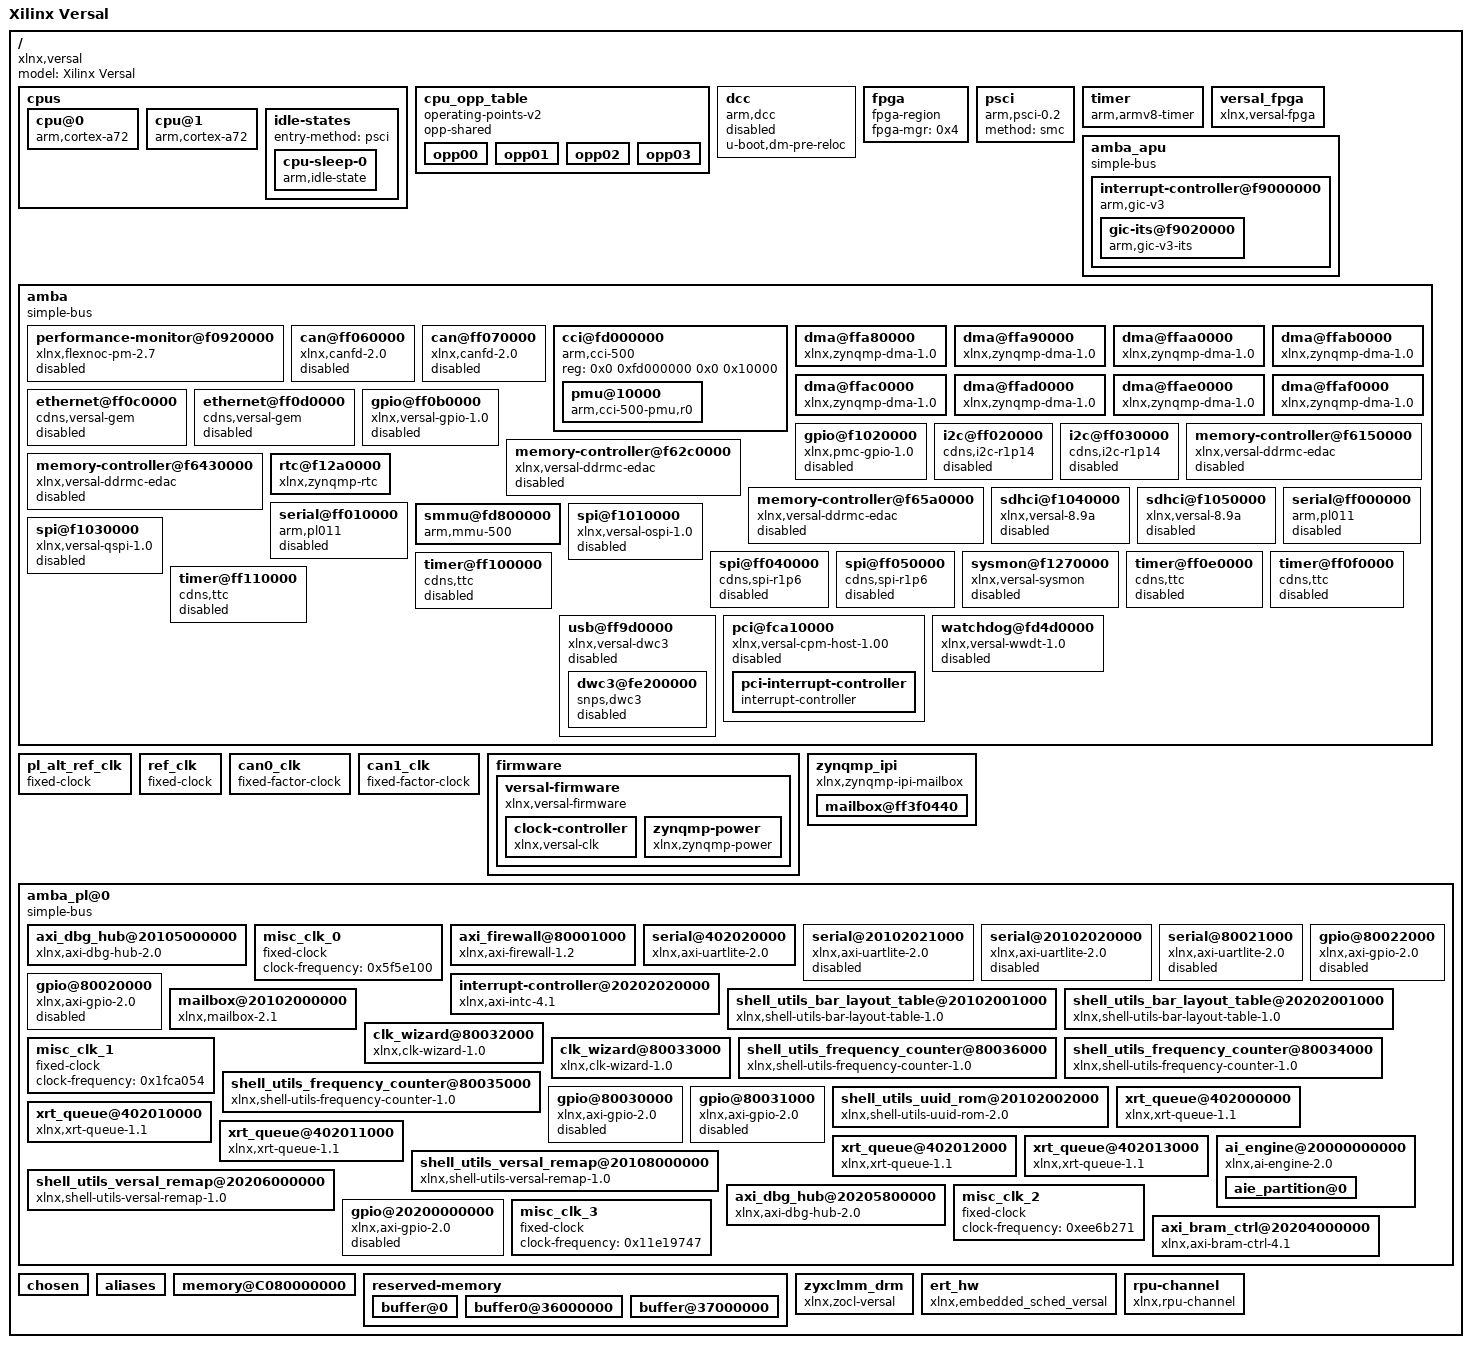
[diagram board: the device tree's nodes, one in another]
/dts-v1/;

/ {
	compatible = "xlnx,versal";
	#address-cells = <0x2>;
	#size-cells = <0x2>;
	model = "Xilinx Versal";

	cpus {
		#address-cells = <0x1>;
		#size-cells = <0x0>;

		cpu@0 {
			compatible = "arm,cortex-a72", "arm,armv8";
			device_type = "cpu";
			enable-method = "psci";
			operating-points-v2 = <0x1>;
			reg = <0x0>;
			cpu-idle-states = <0x2>;
			clocks = <0x3 0x4d>;
		};

		cpu@1 {
			compatible = "arm,cortex-a72", "arm,armv8";
			device_type = "cpu";
			enable-method = "psci";
			operating-points-v2 = <0x1>;
			reg = <0x1>;
			cpu-idle-states = <0x2>;
		};

		idle-states {
			entry-method = "psci";

			cpu-sleep-0 {
				compatible = "arm,idle-state";
				arm,psci-suspend-param = <0x40000000>;
				local-timer-stop;
				entry-latency-us = <0x12c>;
				exit-latency-us = <0x258>;
				min-residency-us = <0x2710>;
				phandle = <0x2>;
			};
		};
	};

	cpu_opp_table {
		compatible = "operating-points-v2";
		opp-shared;
		phandle = <0x1>;

		opp00 {
			opp-hz = <0x0 0x47868bf4>;
			opp-microvolt = <0xf4240>;
			clock-latency-ns = <0x7a120>;
		};

		opp01 {
			opp-hz = <0x0 0x23c345fa>;
			opp-microvolt = <0xf4240>;
			clock-latency-ns = <0x7a120>;
		};

		opp02 {
			opp-hz = <0x0 0x17d783fc>;
			opp-microvolt = <0xf4240>;
			clock-latency-ns = <0x7a120>;
		};

		opp03 {
			opp-hz = <0x0 0x11e1a2fd>;
			opp-microvolt = <0xf4240>;
			clock-latency-ns = <0x7a120>;
		};
	};

	dcc {
		compatible = "arm,dcc";
		status = "disabled";
		u-boot,dm-pre-reloc;
	};

	fpga {
		compatible = "fpga-region";
		fpga-mgr = <0x4>;
		#address-cells = <0x2>;
		#size-cells = <0x2>;
	};

	psci {
		compatible = "arm,psci-0.2";
		method = "smc";
	};

	timer {
		compatible = "arm,armv8-timer";
		interrupt-parent = <0x5>;
		interrupts = <0x1 0xd 0x4 0x1 0xe 0x4 0x1 0xb 0x4 0x1 0xa 0x4>;
	};

	versal_fpga {
		compatible = "xlnx,versal-fpga";
		phandle = <0x4>;
	};

	amba_apu {
		compatible = "simple-bus";
		#address-cells = <0x2>;
		#size-cells = <0x2>;
		ranges;

		interrupt-controller@f9000000 {
			compatible = "arm,gic-v3";
			#interrupt-cells = <0x3>;
			#address-cells = <0x2>;
			#size-cells = <0x2>;
			ranges;
			reg = <0x0 0xf9000000 0x0 0x80000 0x0 0xf9080000 0x0 0x80000>;
			interrupt-controller;
			interrupt-parent = <0x5>;
			interrupts = <0x1 0x9 0x4>;
			num_cpus = <0x2>;
			num_interrupts = <0x60>;
			phandle = <0x5>;

			gic-its@f9020000 {
				compatible = "arm,gic-v3-its";
				msi-controller;
				msi-cells = <0x1>;
				reg = <0x0 0xf9020000 0x0 0x20000>;
				phandle = <0xa>;
			};
		};
	};

	amba {
		compatible = "simple-bus";
		#address-cells = <0x2>;
		#size-cells = <0x2>;
		ranges;
		interrupt-parent = <0x5>;
		u-boot,dm-pre-reloc;

		performance-monitor@f0920000 {
			compatible = "xlnx,flexnoc-pm-2.7";
			status = "disabled";
			reg-names = "funnel", "baselpd", "basefpd";
			reg = <0x0 0xf0920000 0x0 0x1000 0x0 0xf0980000 0x0 0x9000 0x0 0xf0b80000 0x0 0x9000>;
		};

		can@ff060000 {
			compatible = "xlnx,canfd-2.0";
			status = "disabled";
			reg = <0x0 0xff060000 0x0 0x6000>;
			interrupts = <0x0 0x14 0x1>;
			clock-names = "can_clk", "s_axi_aclk";
			rx-fifo-depth = <0x40>;
			tx-mailbox-count = <0x20>;
			clocks = <0x6 0x3 0x52>;
			power-domains = <0x7 0x1822401f>;
		};

		can@ff070000 {
			compatible = "xlnx,canfd-2.0";
			status = "disabled";
			reg = <0x0 0xff070000 0x0 0x6000>;
			interrupts = <0x0 0x15 0x1>;
			clock-names = "can_clk", "s_axi_aclk";
			rx-fifo-depth = <0x40>;
			tx-mailbox-count = <0x20>;
			clocks = <0x8 0x3 0x52>;
			power-domains = <0x7 0x18224020>;
		};

		cci@fd000000 {
			compatible = "arm,cci-500";
			status = "okay";
			reg = <0x0 0xfd000000 0x0 0x10000>;
			ranges = <0x0 0x0 0xfd000000 0xa0000>;
			#address-cells = <0x1>;
			#size-cells = <0x1>;

			pmu@10000 {
				compatible = "arm,cci-500-pmu,r0";
				reg = <0x10000 0x90000>;
				interrupts = <0x0 0x6a 0x4 0x0 0x6a 0x4 0x0 0x6a 0x4 0x0 0x6a 0x4 0x0 0x6a 0x4 0x0 0x6a 0x4 0x0 0x6a 0x4 0x0 0x6a 0x4 0x0 0x6a 0x4>;
			};
		};

		dma@ffa80000 {
			compatible = "xlnx,zynqmp-dma-1.0";
			status = "okay";
			reg = <0x0 0xffa80000 0x0 0x1000>;
			interrupts = <0x0 0x3c 0x4>;
			clock-names = "clk_main", "clk_apb";
			#stream-id-cells = <0x1>;
			xlnx,bus-width = <0x40>;
			clocks = <0x3 0x51 0x3 0x52>;
			power-domains = <0x7 0x18224035>;
		};

		dma@ffa90000 {
			compatible = "xlnx,zynqmp-dma-1.0";
			status = "okay";
			reg = <0x0 0xffa90000 0x0 0x1000>;
			interrupts = <0x0 0x3d 0x4>;
			clock-names = "clk_main", "clk_apb";
			#stream-id-cells = <0x1>;
			xlnx,bus-width = <0x40>;
			clocks = <0x3 0x51 0x3 0x52>;
			power-domains = <0x7 0x18224036>;
		};

		dma@ffaa0000 {
			compatible = "xlnx,zynqmp-dma-1.0";
			status = "okay";
			reg = <0x0 0xffaa0000 0x0 0x1000>;
			interrupts = <0x0 0x3e 0x4>;
			clock-names = "clk_main", "clk_apb";
			#stream-id-cells = <0x1>;
			xlnx,bus-width = <0x40>;
			clocks = <0x3 0x51 0x3 0x52>;
			power-domains = <0x7 0x18224037>;
		};

		dma@ffab0000 {
			compatible = "xlnx,zynqmp-dma-1.0";
			status = "okay";
			reg = <0x0 0xffab0000 0x0 0x1000>;
			interrupts = <0x0 0x3f 0x4>;
			clock-names = "clk_main", "clk_apb";
			#stream-id-cells = <0x1>;
			xlnx,bus-width = <0x40>;
			clocks = <0x3 0x51 0x3 0x52>;
			power-domains = <0x7 0x18224038>;
		};

		dma@ffac0000 {
			compatible = "xlnx,zynqmp-dma-1.0";
			status = "okay";
			reg = <0x0 0xffac0000 0x0 0x1000>;
			interrupts = <0x0 0x40 0x4>;
			clock-names = "clk_main", "clk_apb";
			#stream-id-cells = <0x1>;
			xlnx,bus-width = <0x40>;
			clocks = <0x3 0x51 0x3 0x52>;
			power-domains = <0x7 0x18224039>;
		};

		dma@ffad0000 {
			compatible = "xlnx,zynqmp-dma-1.0";
			status = "okay";
			reg = <0x0 0xffad0000 0x0 0x1000>;
			interrupts = <0x0 0x41 0x4>;
			clock-names = "clk_main", "clk_apb";
			#stream-id-cells = <0x1>;
			xlnx,bus-width = <0x40>;
			clocks = <0x3 0x51 0x3 0x52>;
			power-domains = <0x7 0x1822403a>;
		};

		dma@ffae0000 {
			compatible = "xlnx,zynqmp-dma-1.0";
			status = "okay";
			reg = <0x0 0xffae0000 0x0 0x1000>;
			interrupts = <0x0 0x42 0x4>;
			clock-names = "clk_main", "clk_apb";
			#stream-id-cells = <0x1>;
			xlnx,bus-width = <0x40>;
			clocks = <0x3 0x51 0x3 0x52>;
			power-domains = <0x7 0x1822403b>;
		};

		dma@ffaf0000 {
			compatible = "xlnx,zynqmp-dma-1.0";
			status = "okay";
			reg = <0x0 0xffaf0000 0x0 0x1000>;
			interrupts = <0x0 0x43 0x4>;
			clock-names = "clk_main", "clk_apb";
			#stream-id-cells = <0x1>;
			xlnx,bus-width = <0x40>;
			clocks = <0x3 0x51 0x3 0x52>;
			power-domains = <0x7 0x1822403c>;
		};

		ethernet@ff0c0000 {
			compatible = "cdns,versal-gem";
			status = "disabled";
			reg = <0x0 0xff0c0000 0x0 0x1000>;
			interrupts = <0x0 0x38 0x4 0x0 0x38 0x4>;
			clock-names = "pclk", "hclk", "tx_clk", "rx_clk", "tsu_clk";
			#stream-id-cells = <0x1>;
			#address-cells = <0x1>;
			#size-cells = <0x0>;
			clocks = <0x3 0x52 0x3 0x58 0x3 0x31 0x3 0x30 0x3 0x2b>;
			power-domains = <0x7 0x18224019>;
		};

		ethernet@ff0d0000 {
			compatible = "cdns,versal-gem";
			status = "disabled";
			reg = <0x0 0xff0d0000 0x0 0x1000>;
			interrupts = <0x0 0x3a 0x4 0x0 0x3a 0x4>;
			clock-names = "pclk", "hclk", "tx_clk", "rx_clk", "tsu_clk";
			#stream-id-cells = <0x1>;
			#address-cells = <0x1>;
			#size-cells = <0x0>;
			clocks = <0x3 0x52 0x3 0x59 0x3 0x33 0x3 0x32 0x3 0x2b>;
			power-domains = <0x7 0x1822401a>;
		};

		gpio@ff0b0000 {
			compatible = "xlnx,versal-gpio-1.0";
			status = "disabled";
			reg = <0x0 0xff0b0000 0x0 0x1000>;
			interrupts = <0x0 0xd 0x4>;
			#gpio-cells = <0x2>;
			gpio-controller;
			#interrupt-cells = <0x2>;
			interrupt-controller;
			clocks = <0x3 0x52>;
			power-domains = <0x7 0x18224023>;
		};

		gpio@f1020000 {
			compatible = "xlnx,pmc-gpio-1.0";
			status = "disabled";
			reg = <0x0 0xf1020000 0x0 0x1000>;
			interrupts = <0x0 0x7a 0x4>;
			#gpio-cells = <0x2>;
			gpio-controller;
			#interrupt-cells = <0x2>;
			interrupt-controller;
			clocks = <0x3 0x3d>;
			power-domains = <0x7 0x1822402c>;
		};

		i2c@ff020000 {
			compatible = "cdns,i2c-r1p14", "cdns,i2c-r1p10";
			status = "disabled";
			reg = <0x0 0xff020000 0x0 0x1000>;
			interrupts = <0x0 0xe 0x4>;
			clock-frequency = <0x61a80>;
			#address-cells = <0x1>;
			#size-cells = <0x0>;
			clocks = <0x3 0x62>;
			power-domains = <0x7 0x1822401d>;
		};

		i2c@ff030000 {
			compatible = "cdns,i2c-r1p14", "cdns,i2c-r1p10";
			status = "disabled";
			reg = <0x0 0xff030000 0x0 0x1000>;
			interrupts = <0x0 0xf 0x4>;
			clock-frequency = <0x61a80>;
			#address-cells = <0x1>;
			#size-cells = <0x0>;
			clocks = <0x3 0x63>;
			power-domains = <0x7 0x1822401e>;
		};

		memory-controller@f6150000 {
			compatible = "xlnx,versal-ddrmc-edac";
			status = "disabled";
			reg = <0x0 0xf6150000 0x0 0x2000 0x0 0xf6070000 0x0 0x20000>;
			reg-names = "ddrmc_base", "ddrmc_noc_base";
			interrupt-parent = <0x5>;
			interrupts = <0x0 0x93 0x4>;
			xlnx,mc-id = <0x0>;
		};

		memory-controller@f62c0000 {
			compatible = "xlnx,versal-ddrmc-edac";
			status = "disabled";
			reg = <0x0 0xf62c0000 0x0 0x2000 0x0 0xf6210000 0x0 0x20000>;
			reg-names = "ddrmc_base", "ddrmc_noc_base";
			interrupt-parent = <0x5>;
			interrupts = <0x0 0x93 0x4>;
			xlnx,mc-id = <0x1>;
		};

		memory-controller@f6430000 {
			compatible = "xlnx,versal-ddrmc-edac";
			status = "disabled";
			reg = <0x0 0xf6430000 0x0 0x2000 0x0 0xf6380000 0x0 0x20000>;
			reg-names = "ddrmc_base", "ddrmc_noc_base";
			interrupt-parent = <0x5>;
			interrupts = <0x0 0x93 0x4>;
			xlnx,mc-id = <0x2>;
		};

		memory-controller@f65a0000 {
			compatible = "xlnx,versal-ddrmc-edac";
			status = "disabled";
			reg = <0x0 0xf65a0000 0x0 0x2000 0x0 0xf64f0000 0x0 0x20000>;
			reg-names = "ddrmc_base", "ddrmc_noc_base";
			interrupt-parent = <0x5>;
			interrupts = <0x0 0x93 0x4>;
			xlnx,mc-id = <0x3>;
		};

		rtc@f12a0000 {
			compatible = "xlnx,zynqmp-rtc";
			status = "okay";
			reg = <0x0 0xf12a0000 0x0 0x100>;
			interrupt-names = "alarm", "sec";
			interrupts = <0x0 0x8e 0x4 0x0 0x8f 0x4>;
			calibration = <0x8000>;
			power-domains = <0x7 0x18224034>;
		};

		sdhci@f1040000 {
			compatible = "xlnx,versal-8.9a", "arasan,sdhci-8.9a";
			status = "disabled";
			reg = <0x0 0xf1040000 0x0 0x10000>;
			interrupts = <0x0 0x7e 0x4 0x0 0x7e 0x4>;
			clock-names = "clk_xin", "clk_ahb";
			xlnx,device_id = <0x0>;
			#stream-id-cells = <0x1>;
			#clock-cells = <0x1>;
			clock-output-names = "clk_out_sd0", "clk_in_sd0";
			clocks = <0x3 0x3b 0x3 0x52>;
			power-domains = <0x7 0x1822402e>;
		};

		sdhci@f1050000 {
			compatible = "xlnx,versal-8.9a", "arasan,sdhci-8.9a";
			status = "disabled";
			reg = <0x0 0xf1050000 0x0 0x10000>;
			interrupts = <0x0 0x80 0x4 0x0 0x80 0x4>;
			clock-names = "clk_xin", "clk_ahb";
			xlnx,device_id = <0x1>;
			#stream-id-cells = <0x1>;
			#clock-cells = <0x1>;
			clock-output-names = "clk_out_sd1", "clk_in_sd1";
			clocks = <0x3 0x3c 0x3 0x52>;
			power-domains = <0x7 0x1822402f>;
		};

		serial@ff000000 {
			compatible = "arm,pl011", "arm,sbsa-uart";
			status = "disabled";
			reg = <0x0 0xff000000 0x0 0x1000>;
			interrupts = <0x0 0x12 0x4>;
			clock-names = "uart_clk", "apb_clk";
			current-speed = <0x1c200>;
			u-boot,dm-pre-reloc;
			clocks = <0x3 0x5c 0x3 0x52>;
			power-domains = <0x7 0x18224021>;
			cts-override;
			device_type = "serial";
			port-number = <0x1>;
		};

		serial@ff010000 {
			compatible = "arm,pl011", "arm,sbsa-uart";
			status = "disabled";
			reg = <0x0 0xff010000 0x0 0x1000>;
			interrupts = <0x0 0x13 0x4>;
			clock-names = "uart_clk", "apb_clk";
			current-speed = <0x1c200>;
			u-boot,dm-pre-reloc;
			clocks = <0x3 0x5d 0x3 0x52>;
			power-domains = <0x7 0x18224022>;
			cts-override;
			device_type = "serial";
			port-number = <0x0>;
		};

		smmu@fd800000 {
			compatible = "arm,mmu-500";
			status = "okay";
			reg = <0x0 0xfd800000 0x0 0x40000>;
			stream-match-mask = <0x7c00>;
			#iommu-cells = <0x1>;
			#global-interrupts = <0x1>;
			interrupts = <0x0 0x6b 0x4 0x0 0x6b 0x4 0x0 0x6b 0x4 0x0 0x6b 0x4 0x0 0x6b 0x4 0x0 0x6b 0x4 0x0 0x6b 0x4 0x0 0x6b 0x4 0x0 0x6b 0x4 0x0 0x6b 0x4 0x0 0x6b 0x4 0x0 0x6b 0x4 0x0 0x6b 0x4 0x0 0x6b 0x4 0x0 0x6b 0x4 0x0 0x6b 0x4 0x0 0x6b 0x4 0x0 0x6b 0x4 0x0 0x6b 0x4 0x0 0x6b 0x4 0x0 0x6b 0x4 0x0 0x6b 0x4 0x0 0x6b 0x4 0x0 0x6b 0x4 0x0 0x6b 0x4 0x0 0x6b 0x4 0x0 0x6b 0x4 0x0 0x6b 0x4 0x0 0x6b 0x4 0x0 0x6b 0x4 0x0 0x6b 0x4 0x0 0x6b 0x4 0x0 0x6b 0x4>;
		};

		spi@f1010000 {
			compatible = "xlnx,versal-ospi-1.0", "cadence,qspi", "cdns,qspi-nor";
			status = "disabled";
			reg = <0x0 0xf1010000 0x0 0x10000 0x0 0xc0000000 0x0 0x20000000>;
			interrupts = <0x0 0x7c 0x4 0x0 0x7c 0x4>;
			clock-names = "ref_clk", "pclk";
			cdns,fifo-depth = <0x100>;
			cdns,fifo-width = <0x4>;
			cdns,is-dma = <0x1>;
			cdns,is-stig-pgm = <0x1>;
			cdns,trigger-address = <0xc0000000>;
			#stream-id-cells = <0x1>;
			#address-cells = <0x1>;
			#size-cells = <0x0>;
			clocks = <0x3 0x3a 0x3 0x52>;
			power-domains = <0x7 0x1822402a>;
			is-dual = <0x0>;
			is-stacked = <0x0>;
		};

		spi@f1030000 {
			compatible = "xlnx,versal-qspi-1.0";
			status = "disabled";
			reg = <0x0 0xf1030000 0x0 0x1000>;
			interrupts = <0x0 0x7d 0x4 0x0 0x7d 0x4>;
			clock-names = "ref_clk", "pclk";
			#stream-id-cells = <0x1>;
			#address-cells = <0x1>;
			#size-cells = <0x0>;
			clocks = <0x3 0x39 0x3 0x52>;
			power-domains = <0x7 0x1822402b>;
		};

		spi@ff040000 {
			compatible = "cdns,spi-r1p6";
			status = "disabled";
			reg = <0x0 0xff040000 0x0 0x1000>;
			interrupts = <0x0 0x10 0x4>;
			clock-names = "ref_clk", "pclk";
			#address-cells = <0x1>;
			#size-cells = <0x0>;
			clocks = <0x3 0x5e 0x3 0x52>;
			power-domains = <0x7 0x1822401b>;
		};

		spi@ff050000 {
			compatible = "cdns,spi-r1p6";
			status = "disabled";
			reg = <0x0 0xff050000 0x0 0x1000>;
			interrupts = <0x0 0x11 0x4>;
			clock-names = "ref_clk", "pclk";
			#address-cells = <0x1>;
			#size-cells = <0x0>;
			clocks = <0x3 0x5f 0x3 0x52>;
			power-domains = <0x7 0x1822401c>;
		};

		sysmon@f1270000 {
			compatible = "xlnx,versal-sysmon";
			status = "disabled";
			reg = <0x0 0xf1270000 0x0 0x4000>;
			interrupts = <0x0 0x90 0x4>;
			xlnx,numchannels = [00];
			#address-cells = <0x1>;
			#size-cells = <0x0>;
		};

		timer@ff0e0000 {
			compatible = "cdns,ttc";
			status = "disabled";
			interrupts = <0x0 0x25 0x4 0x0 0x26 0x4 0x0 0x27 0x4>;
			reg = <0x0 0xff0e0000 0x0 0x1000>;
			timer-width = <0x20>;
			clocks = <0x3 0x27 0x3 0x52>;
			power-domains = <0x7 0x18224024>;
		};

		timer@ff0f0000 {
			compatible = "cdns,ttc";
			status = "disabled";
			interrupts = <0x0 0x28 0x4 0x0 0x29 0x4 0x0 0x2a 0x4>;
			reg = <0x0 0xff0f0000 0x0 0x1000>;
			timer-width = <0x20>;
			clocks = <0x3 0x28 0x3 0x52>;
			power-domains = <0x7 0x18224025>;
		};

		timer@ff100000 {
			compatible = "cdns,ttc";
			status = "disabled";
			interrupts = <0x0 0x2b 0x4 0x0 0x2c 0x4 0x0 0x2d 0x4>;
			reg = <0x0 0xff100000 0x0 0x1000>;
			timer-width = <0x20>;
			clocks = <0x3 0x29 0x3 0x52>;
			power-domains = <0x7 0x18224026>;
		};

		timer@ff110000 {
			compatible = "cdns,ttc";
			status = "disabled";
			interrupts = <0x0 0x2e 0x4 0x0 0x2f 0x4 0x0 0x30 0x4>;
			reg = <0x0 0xff110000 0x0 0x1000>;
			timer-width = <0x20>;
			clocks = <0x3 0x2a 0x3 0x52>;
			power-domains = <0x7 0x18224027>;
		};

		usb@ff9d0000 {
			compatible = "xlnx,versal-dwc3";
			status = "disabled";
			reg = <0x0 0xff9d0000 0x0 0x100>;
			clock-names = "bus_clk", "ref_clk";
			ranges;
			#address-cells = <0x2>;
			#size-cells = <0x2>;
			clocks = <0x3 0x5b 0x3 0x68>;
			power-domains = <0x7 0x18224018>;

			dwc3@fe200000 {
				compatible = "snps,dwc3";
				status = "disabled";
				reg = <0x0 0xfe200000 0x0 0x10000>;
				interrupt-names = "dwc_usb3", "otg", "usb-wakeup";
				interrupts = <0x0 0x16 0x4 0x0 0x1a 0x4 0x0 0x4a 0x4>;
				#stream-id-cells = <0x1>;
				snps,dis_u2_susphy_quirk;
				snps,dis_u3_susphy_quirk;
				snps,quirk-frame-length-adjustment = <0x20>;
				snps,refclk_fladj;
				snps,mask_phy_reset;
			};
		};

		pci@fca10000 {
			#address-cells = <0x3>;
			#interrupt-cells = <0x1>;
			#size-cells = <0x2>;
			compatible = "xlnx,versal-cpm-host-1.00";
			status = "disabled";
			interrupt-map = <0x0 0x0 0x0 0x1 0x9 0x1 0x0 0x0 0x0 0x2 0x9 0x2 0x0 0x0 0x0 0x3 0x9 0x3 0x0 0x0 0x0 0x4 0x9 0x4>;
			interrupt-map-mask = <0x0 0x0 0x0 0x7>;
			interrupt-parent = <0x5>;
			interrupt-names = "misc";
			interrupts = <0x0 0x48 0x4>;
			ranges = <0x2000000 0x0 0xe0000000 0x0 0xe0000000 0x0 0x10000000 0x43000000 0x80 0x0 0x80 0x0 0x0 0x80000000>;
			msi-map = <0x0 0xa 0x0 0x10000>;
			reg = <0x0 0xfca10000 0x0 0x1000 0x6 0x0 0x0 0x1000000>;
			reg-names = "cpm_slcr", "cfg";

			pci-interrupt-controller {
				#address-cells = <0x0>;
				#interrupt-cells = <0x1>;
				interrupt-controller;
				phandle = <0x9>;
			};
		};

		watchdog@fd4d0000 {
			compatible = "xlnx,versal-wwdt-1.0";
			status = "disabled";
			reg = <0x0 0xfd4d0000 0x0 0x10000>;
			interrupt-names = "wdt", "wwdt_reset_pending";
			interrupts = <0x0 0x64 0x1 0x0 0x6d 0x1>;
			timeout-sec = <0x1e>;
			pretimeout-sec = <0x19>;
			clocks = <0x3 0x52>;
			power-domains = <0x7 0x18224029>;
		};
	};

	pl_alt_ref_clk {
		u-boot,dm-pre-reloc;
		compatible = "fixed-clock";
		#clock-cells = <0x0>;
		clock-frequency = <0x1fca055>;
		phandle = <0xc>;
	};

	ref_clk {
		u-boot,dm-pre-reloc;
		compatible = "fixed-clock";
		#clock-cells = <0x0>;
		clock-frequency = <0x1fca055>;
		phandle = <0xb>;
	};

	can0_clk {
		#clock-cells = <0x0>;
		compatible = "fixed-factor-clock";
		clocks = <0x3 0x60>;
		clock-div = <0x2>;
		clock-mult = <0x1>;
		phandle = <0x6>;
	};

	can1_clk {
		#clock-cells = <0x0>;
		compatible = "fixed-factor-clock";
		clocks = <0x3 0x61>;
		clock-div = <0x2>;
		clock-mult = <0x1>;
		phandle = <0x8>;
	};

	firmware {

		versal-firmware {
			compatible = "xlnx,versal-firmware";
			u-boot,dm-pre-reloc;
			method = "smc";
			#power-domain-cells = <0x1>;
			interrupt-parent = <0x5>;
			phandle = <0x7>;

			clock-controller {
				u-boot,dm-pre-reloc;
				#clock-cells = <0x1>;
				compatible = "xlnx,versal-clk";
				clocks = <0xb 0xc>;
				clock-names = "ref_clk", "pl_alt_ref_clk";
				phandle = <0x3>;
			};

			zynqmp-power {
				compatible = "xlnx,zynqmp-power";
				interrupt-parent = <0x5>;
				interrupts = <0x0 0x1e 0x4>;
				mboxes = <0xd 0x0 0xd 0x1>;
				mbox-names = "tx", "rx";
			};
		};
	};

	zynqmp_ipi {
		compatible = "xlnx,zynqmp-ipi-mailbox";
		interrupt-parent = <0x5>;
		interrupts = <0x0 0x1e 0x4>;
		xlnx,ipi-id = <0x2>;
		#address-cells = <0x2>;
		#size-cells = <0x2>;
		ranges;

		mailbox@ff3f0440 {
			reg = <0x0 0xff3f0440 0x0 0x20 0x0 0xff3f0460 0x0 0x20 0x0 0xff3f0280 0x0 0x20 0x0 0xff3f02a0 0x0 0x20>;
			reg-names = "local_request_region", "local_response_region", "remote_request_region", "remote_response_region";
			#mbox-cells = <0x1>;
			xlnx,ipi-id = <0x1>;
			phandle = <0xd>;
		};
	};

	amba_pl@0 {
		#address-cells = <0x2>;
		#size-cells = <0x2>;
		compatible = "simple-bus";
		ranges;

		axi_dbg_hub@20105000000 {
			clock-names = "aclk";
			clocks = <0xe>;
			compatible = "xlnx,axi-dbg-hub-2.0";
			reg = <0x201 0x5000000 0x0 0x200000>;
			xlnx,addr-offset = <0x201 0x5000000>;
			xlnx,addr-range = <0x200000>;
			xlnx,axi-addr-width = <0x40>;
			xlnx,axi-data-width = <0x80>;
			xlnx,axi-id-width = <0x2>;
			xlnx,axis-tdata-width = <0x20>;
			xlnx,num-debug-cores = <0x0>;
			xlnx,num-rd-outstanding-txn = <0x1>;
			xlnx,num-wr-outstanding-txn = <0x1>;
		};

		misc_clk_0 {
			#clock-cells = <0x0>;
			clock-frequency = <0x5f5e100>;
			compatible = "fixed-clock";
			phandle = <0xe>;
		};

		axi_firewall@80001000 {
			clock-names = "aclk";
			clocks = <0xe>;
			compatible = "xlnx,axi-firewall-1.2";
			reg = <0x0 0x80001000 0x0 0x1000>;
			xlnx,addr-width = <0x40>;
			xlnx,aruser-width = <0x0>;
			xlnx,awuser-width = <0x0>;
			xlnx,buser-width = <0x0>;
			xlnx,enable-ctl-clock = <0x0>;
			xlnx,enable-initial-delay = <0x1>;
			xlnx,enable-pipelining = <0x1>;
			xlnx,enable-prescaler = <0x1>;
			xlnx,enable-protocol-checks = <0x1>;
			xlnx,enable-timeout-checks = <0x1>;
			xlnx,firewall-mode = <0x0>;
			xlnx,id-width = <0x0>;
			xlnx,mask-err-resp = <0x1>;
			xlnx,num-read-outstanding = <0x20>;
			xlnx,num-read-threads = <0x1>;
			xlnx,num-write-outstanding = <0x20>;
			xlnx,num-write-threads = <0x1>;
			xlnx,protocol = <0x2>;
			xlnx,rdata-width = <0x20>;
			xlnx,ruser-width = <0x0>;
			xlnx,wdata-width = <0x20>;
			xlnx,wuser-width = <0x0>;
		};

		serial@402020000 {
			clock-names = "s_axi_aclk";
			clocks = <0xe>;
			compatible = "xlnx,axi-uartlite-2.0", "xlnx,xps-uartlite-1.00.a";
			current-speed = <0x38400>;
			device_type = "serial";
			interrupt-names = "interrupt";
			interrupt-parent = <0x5>;
			interrupts = <0x0 0x5e 0x1>;
			port-number = <0x0>;
			reg = <0x4 0x2020000 0x0 0x1000>;
			xlnx,baudrate = <0x38400>;
			xlnx,data-bits = <0x8>;
			xlnx,odd-parity = <0x0>;
			xlnx,s-axi-aclk-freq-hz-d = "100.0";
			xlnx,use-parity = <0x0>;
		};

		serial@20102021000 {
			status = "disabled";
			clock-names = "s_axi_aclk";
			clocks = <0xe>;
			compatible = "xlnx,axi-uartlite-2.0", "xlnx,xps-uartlite-1.00.a";
			current-speed = <0x38400>;
			device_type = "serial";
			port-number = <0x2>;
			reg = <0x201 0x2021000 0x0 0x1000>;
			xlnx,baudrate = <0x38400>;
			xlnx,data-bits = <0x8>;
			xlnx,odd-parity = <0x0>;
			xlnx,s-axi-aclk-freq-hz-d = "100.0";
			xlnx,use-parity = <0x0>;
		};

		serial@20102020000 {
			status = "disabled";
			clock-names = "s_axi_aclk";
			clocks = <0xe>;
			compatible = "xlnx,axi-uartlite-2.0", "xlnx,xps-uartlite-1.00.a";
			current-speed = <0x38400>;
			device_type = "serial";
			port-number = <0x3>;
			reg = <0x201 0x2020000 0x0 0x1000>;
			xlnx,baudrate = <0x38400>;
			xlnx,data-bits = <0x8>;
			xlnx,odd-parity = <0x0>;
			xlnx,s-axi-aclk-freq-hz-d = "100.0";
			xlnx,use-parity = <0x0>;
		};

		serial@80021000 {
			status = "disabled";
			clock-names = "s_axi_aclk";
			clocks = <0xe>;
			compatible = "xlnx,axi-uartlite-2.0", "xlnx,xps-uartlite-1.00.a";
			current-speed = <0x38400>;
			device_type = "serial";
			port-number = <0x4>;
			reg = <0x0 0x80021000 0x0 0x1000>;
			xlnx,baudrate = <0x38400>;
			xlnx,data-bits = <0x8>;
			xlnx,odd-parity = <0x0>;
			xlnx,s-axi-aclk-freq-hz-d = "100.0";
			xlnx,use-parity = <0x0>;
		};

		gpio@80022000 {
			status = "disabled";
			#gpio-cells = <0x3>;
			clock-names = "s_axi_aclk";
			clocks = <0xe>;
			compatible = "xlnx,axi-gpio-2.0", "xlnx,xps-gpio-1.00.a";
			gpio-controller;
			reg = <0x0 0x80022000 0x0 0x1000>;
			xlnx,all-inputs = <0x0>;
			xlnx,all-inputs-2 = <0x1>;
			xlnx,all-outputs = <0x1>;
			xlnx,all-outputs-2 = <0x0>;
			xlnx,dout-default = <0x0>;
			xlnx,dout-default-2 = <0x0>;
			xlnx,gpio-width = <0x1>;
			xlnx,gpio2-width = <0x1>;
			xlnx,interrupt-present = <0x0>;
			xlnx,is-dual = <0x1>;
			xlnx,tri-default = <0xffffffff>;
			xlnx,tri-default-2 = <0xffffffff>;
		};

		gpio@80020000 {
			status = "disabled";
			#gpio-cells = <0x3>;
			clock-names = "s_axi_aclk";
			clocks = <0xe>;
			compatible = "xlnx,axi-gpio-2.0", "xlnx,xps-gpio-1.00.a";
			gpio-controller;
			reg = <0x0 0x80020000 0x0 0x1000>;
			xlnx,all-inputs = <0x0>;
			xlnx,all-inputs-2 = <0x1>;
			xlnx,all-outputs = <0x1>;
			xlnx,all-outputs-2 = <0x0>;
			xlnx,dout-default = <0xffffffff>;
			xlnx,dout-default-2 = <0x0>;
			xlnx,gpio-width = <0x2>;
			xlnx,gpio2-width = <0x2>;
			xlnx,interrupt-present = <0x0>;
			xlnx,is-dual = <0x1>;
			xlnx,tri-default = <0xffffffff>;
			xlnx,tri-default-2 = <0xffffffff>;
		};

		interrupt-controller@20202020000 {
			#interrupt-cells = <0x2>;
			clock-names = "s_axi_aclk";
			clocks = <0xe>;
			compatible = "xlnx,axi-intc-4.1", "xlnx,xps-intc-1.00.a";
			interrupt-controller;
			interrupt-names = "irq";
			interrupt-parent = <0x5>;
			interrupts = <0x0 0x5d 0x4>;
			reg = <0x202 0x2020000 0x0 0x1000>;
			xlnx,kind-of-intr = <0xffffffff>;
			xlnx,num-intr-inputs = <0x20>;
		};

		shell_utils_bar_layout_table@20102001000 {
			clock-names = "S_AXI_ACLK";
			clocks = <0xe>;
			compatible = "xlnx,shell-utils-bar-layout-table-1.0";
			reg = <0x201 0x2001000 0x0 0x1000>;
			xlnx,entry-addr-0 = <0x0 0x2002000>;
			xlnx,entry-addr-1 = <0x0 0x2000000>;
			xlnx,entry-addr-2 = <0x0 0x2010000>;
			xlnx,entry-addr-3 = <0x0 0x8000000>;
			xlnx,entry-addr-4 = <0x0 0x0>;
			xlnx,entry-addr-5 = <0x0 0x0>;
			xlnx,entry-bar-0 = <0x0>;
			xlnx,entry-bar-1 = <0x0>;
			xlnx,entry-bar-2 = <0x0>;
			xlnx,entry-bar-3 = <0x0>;
			xlnx,entry-bar-4 = <0x0>;
			xlnx,entry-bar-5 = <0x0>;
			xlnx,entry-major-version-0 = <0x1>;
			xlnx,entry-major-version-1 = <0x1>;
			xlnx,entry-major-version-2 = <0x1>;
			xlnx,entry-major-version-3 = <0x1>;
			xlnx,entry-major-version-4 = <0x0>;
			xlnx,entry-major-version-5 = <0x0>;
			xlnx,entry-minor-version-0 = <0x0>;
			xlnx,entry-minor-version-1 = <0x0>;
			xlnx,entry-minor-version-2 = <0x1>;
			xlnx,entry-minor-version-3 = <0x0>;
			xlnx,entry-minor-version-4 = <0x0>;
			xlnx,entry-minor-version-5 = <0x0>;
			xlnx,entry-rsvd0-0 = <0x0>;
			xlnx,entry-rsvd0-1 = <0x3>;
			xlnx,entry-rsvd0-2 = <0x0>;
			xlnx,entry-rsvd0-3 = <0x0>;
			xlnx,entry-rsvd0-4 = <0x0>;
			xlnx,entry-rsvd0-5 = <0x0>;
			xlnx,entry-type-0 = <0x50>;
			xlnx,entry-type-1 = <0x53>;
			xlnx,entry-type-2 = <0x54>;
			xlnx,entry-type-3 = <0x55>;
			xlnx,entry-type-4 = <0x0>;
			xlnx,entry-type-5 = <0x0>;
			xlnx,entry-version-type-0 = <0x1>;
			xlnx,entry-version-type-1 = <0x1>;
			xlnx,entry-version-type-2 = <0x1>;
			xlnx,entry-version-type-3 = <0x1>;
			xlnx,entry-version-type-4 = <0x0>;
			xlnx,entry-version-type-5 = <0x0>;
			xlnx,num-table-entries = <0x4>;
			xlnx,xdevicefamily = "versal";
		};

		shell_utils_bar_layout_table@20202001000 {
			clock-names = "S_AXI_ACLK";
			clocks = <0xe>;
			compatible = "xlnx,shell-utils-bar-layout-table-1.0";
			reg = <0x202 0x2001000 0x0 0x1000>;
			xlnx,entry-addr-0 = <0x0 0x2000000>;
			xlnx,entry-addr-1 = <0x0 0x0>;
			xlnx,entry-addr-2 = <0x0 0x0>;
			xlnx,entry-addr-3 = <0x0 0x0>;
			xlnx,entry-addr-4 = <0x0 0x0>;
			xlnx,entry-addr-5 = <0x0 0x0>;
			xlnx,entry-bar-0 = <0x2>;
			xlnx,entry-bar-1 = <0x0>;
			xlnx,entry-bar-2 = <0x0>;
			xlnx,entry-bar-3 = <0x0>;
			xlnx,entry-bar-4 = <0x0>;
			xlnx,entry-bar-5 = <0x0>;
			xlnx,entry-major-version-0 = <0x1>;
			xlnx,entry-major-version-1 = <0x0>;
			xlnx,entry-major-version-2 = <0x0>;
			xlnx,entry-major-version-3 = <0x0>;
			xlnx,entry-major-version-4 = <0x0>;
			xlnx,entry-major-version-5 = <0x0>;
			xlnx,entry-minor-version-0 = <0x0>;
			xlnx,entry-minor-version-1 = <0x0>;
			xlnx,entry-minor-version-2 = <0x0>;
			xlnx,entry-minor-version-3 = <0x0>;
			xlnx,entry-minor-version-4 = <0x0>;
			xlnx,entry-minor-version-5 = <0x0>;
			xlnx,entry-rsvd0-0 = <0x1>;
			xlnx,entry-rsvd0-1 = <0x0>;
			xlnx,entry-rsvd0-2 = <0x0>;
			xlnx,entry-rsvd0-3 = <0x0>;
			xlnx,entry-rsvd0-4 = <0x0>;
			xlnx,entry-rsvd0-5 = <0x0>;
			xlnx,entry-type-0 = <0x53>;
			xlnx,entry-type-1 = <0x0>;
			xlnx,entry-type-2 = <0x0>;
			xlnx,entry-type-3 = <0x0>;
			xlnx,entry-type-4 = <0x0>;
			xlnx,entry-type-5 = <0x0>;
			xlnx,entry-version-type-0 = <0x1>;
			xlnx,entry-version-type-1 = <0x0>;
			xlnx,entry-version-type-2 = <0x0>;
			xlnx,entry-version-type-3 = <0x0>;
			xlnx,entry-version-type-4 = <0x0>;
			xlnx,entry-version-type-5 = <0x0>;
			xlnx,num-table-entries = <0x1>;
			xlnx,xdevicefamily = "versal";
		};

		mailbox@20102000000 {
			clock-names = "S0_AXI_ACLK", "S1_AXI_ACLK";
			clocks = <0xe 0xe>;
			compatible = "xlnx,mailbox-2.1";
			reg = <0x201 0x2000000 0x0 0x1000 0x202 0x2000000 0x0 0x1000>;
			xlnx,async-clks = <0x0>;
			xlnx,async-interrupts = <0x1>;
			xlnx,enable-bus-error = <0x0>;
			xlnx,ext-reset-high = <0x1>;
			xlnx,impl-style = <0x0>;
			xlnx,interconnect-port-0 = <0x2>;
			xlnx,interconnect-port-1 = <0x2>;
			xlnx,mailbox-depth = <0x10>;
			xlnx,num-sync-ff = <0x2>;
			xlnx,read-clock-period-0 = <0x0>;
			xlnx,read-clock-period-1 = <0x0>;
			xlnx,s0-axi-aclk-freq-mhz = "100.0";
			xlnx,s0-axi-addr-width = <0x20>;
			xlnx,s0-axi-data-width = <0x20>;
			xlnx,s1-axi-aclk-freq-mhz = "100.0";
			xlnx,s1-axi-addr-width = <0x20>;
			xlnx,s1-axi-data-width = <0x20>;
		};

		clk_wizard@80032000 {
			clock-names = "s_axi_aclk", "clk_in1";
			clocks = <0xe 0xf>;
			compatible = "xlnx,clk-wizard-1.0";
			reg = <0x0 0x80032000 0x0 0x1000>;
			xlnx,actual-pfd = "11.11100";
			xlnx,actual-vco = "2999.97000";
			xlnx,auto-nummbufgce = <0x0>;
			xlnx,auto-primitive = "MMCM";
			xlnx,bandwidth = "OPTIMIZED";
			xlnx,bufgce-div-ce-type = "SYNC";
			xlnx,cddcdone-port = "cddcdone";
			xlnx,cddcreq-port = "cddcreq";
			xlnx,ce-sync-ext = <0x0>;
			xlnx,ce-type = "SYNC";
			xlnx,clk-in-sel-port = "clk_in_sel";
			xlnx,clk-out1-port = "clk_out1";
			xlnx,clk-out2-port = "clk_out2";
			xlnx,clk-out3-port = "clk_out3";
			xlnx,clk-out4-port = "clk_out4";
			xlnx,clk-out5-port = "clk_out5";
			xlnx,clk-out6-port = "clk_out6";
			xlnx,clk-out7-port = "clk_out7";
			xlnx,clk-tree1 = <0x0>;
			xlnx,clk-tree2 = <0x0>;
			xlnx,clk-tree3 = <0x0>;
			xlnx,clk-tree4 = <0x0>;
			xlnx,clk-tree5 = <0x0>;
			xlnx,clk-tree6 = <0x0>;
			xlnx,clk-tree7 = <0x0>;
			xlnx,clkfb-bufg = <0x0>;
			xlnx,clkfb-deskew-port = "clkfb_deskew";
			xlnx,clkfb-in-port = "clkfb_in";
			xlnx,clkfb-in-signaling = "SINGLE";
			xlnx,clkfb-out-port = "clkfb_out";
			xlnx,clkfb-stopped-port = "clkfb_stopped";
			xlnx,clkfb1-deskew-port = "clkfb1_deskew";
			xlnx,clkfb2-deskew-port = "clkfb2_deskew";
			xlnx,clkfbin-ibuf = <0x0>;
			xlnx,clkfbin-ibufds = <0x0>;
			xlnx,clkfbin-obuf = <0x0>;
			xlnx,clkfbin-obufds = <0x0>;
			xlnx,clkfbout-bufg = <0x0>;
			xlnx,clkfbout-fract = <0x0>;
			xlnx,clkfbout-mult = <0x1>;
			xlnx,clkfbout-oddr = <0x0>;
			xlnx,clkfbout-phase = "0.000";
			xlnx,clkin-deskew-port = "clkin_deskew";
			xlnx,clkin1-bufg = <0x0>;
			xlnx,clkin1-deskew-port = "clkin1_deskew";
			xlnx,clkin1-ibuf = <0x0>;
			xlnx,clkin1-ibufds = <0x0>;
			xlnx,clkin1-jitter-ps = "100.0";
			xlnx,clkin1-period = "30.00030";
			xlnx,clkin2-bufg = <0x0>;
			xlnx,clkin2-deskew-port = "clkin2_deskew";
			xlnx,clkin2-ibuf = <0x0>;
			xlnx,clkin2-ibufds = <0x0>;
			xlnx,clkin2-jitter-ps = "100.0";
			xlnx,clkin2-period = "20.83333";
			xlnx,clkout1-actual-duty-cycle = "50.00";
			xlnx,clkout1-actual-out-freq = "299.99700";
			xlnx,clkout1-actual-phase = "0.000";
			xlnx,clkout1-divide = <0xa>;
			xlnx,clkout1-drives = "No_buffer";
			xlnx,clkout1-dyn-ps = <0x0>;
			xlnx,clkout1-grouping = "Auto";
			xlnx,clkout1-matched-routing = <0x0>;
			xlnx,clkout1-mbufgce-mode = "PERFORMANCE";
			xlnx,clkout1-requested-duty-cycle = "50.000";
			xlnx,clkout1-requested-out-freq = "100.000";
			xlnx,clkout1-requested-phase = "0.000";
			xlnx,clkout1-sequence-number = <0x1>;
			xlnx,clkout1-used = <0x1>;
			xlnx,clkout2-actual-duty-cycle = "50.00";
			xlnx,clkout2-actual-out-freq = "99.99900";
			xlnx,clkout2-actual-phase = "0.000";
			xlnx,clkout2-divide = <0xc>;
			xlnx,clkout2-drives = "BUFG";
			xlnx,clkout2-dyn-ps = <0x0>;
			xlnx,clkout2-grouping = "Auto";
			xlnx,clkout2-matched-routing = <0x0>;
			xlnx,clkout2-mbufgce-mode = "PERFORMANCE";
			xlnx,clkout2-requested-duty-cycle = "50.000";
			xlnx,clkout2-requested-out-freq = "100.000";
			xlnx,clkout2-requested-phase = "0.000";
			xlnx,clkout2-sequence-number = <0x1>;
			xlnx,clkout2-used = <0x0>;
			xlnx,clkout3-actual-duty-cycle = "50.00";
			xlnx,clkout3-actual-out-freq = "99.99900";
			xlnx,clkout3-actual-phase = "0.000";
			xlnx,clkout3-divide = <0xc>;
			xlnx,clkout3-drives = "BUFG";
			xlnx,clkout3-dyn-ps = <0x0>;
			xlnx,clkout3-grouping = "Auto";
			xlnx,clkout3-matched-routing = <0x0>;
			xlnx,clkout3-mbufgce-mode = "PERFORMANCE";
			xlnx,clkout3-requested-duty-cycle = "50.000";
			xlnx,clkout3-requested-out-freq = "100.000";
			xlnx,clkout3-requested-phase = "0.000";
			xlnx,clkout3-sequence-number = <0x1>;
			xlnx,clkout3-used = <0x0>;
			xlnx,clkout4-actual-duty-cycle = "50.00";
			xlnx,clkout4-actual-out-freq = "99.99900";
			xlnx,clkout4-actual-phase = "0.000";
			xlnx,clkout4-divide = <0xc>;
			xlnx,clkout4-drives = "BUFG";
			xlnx,clkout4-dyn-ps = <0x0>;
			xlnx,clkout4-grouping = "Auto";
			xlnx,clkout4-matched-routing = <0x0>;
			xlnx,clkout4-mbufgce-mode = "PERFORMANCE";
			xlnx,clkout4-requested-duty-cycle = "50.000";
			xlnx,clkout4-requested-out-freq = "100.000";
			xlnx,clkout4-requested-phase = "0.000";
			xlnx,clkout4-sequence-number = <0x1>;
			xlnx,clkout4-used = <0x0>;
			xlnx,clkout5-actual-duty-cycle = "50.00";
			xlnx,clkout5-actual-out-freq = "99.99900";
			xlnx,clkout5-actual-phase = "0.000";
			xlnx,clkout5-divide = <0xc>;
			xlnx,clkout5-drives = "BUFG";
			xlnx,clkout5-dyn-ps = <0x0>;
			xlnx,clkout5-grouping = "Auto";
			xlnx,clkout5-matched-routing = <0x0>;
			xlnx,clkout5-mbufgce-mode = "PERFORMANCE";
			xlnx,clkout5-requested-duty-cycle = "50.000";
			xlnx,clkout5-requested-out-freq = "100.000";
			xlnx,clkout5-requested-phase = "0.000";
			xlnx,clkout5-sequence-number = <0x1>;
			xlnx,clkout5-used = <0x0>;
			xlnx,clkout6-actual-duty-cycle = "50.00";
			xlnx,clkout6-actual-out-freq = "99.99900";
			xlnx,clkout6-actual-phase = "0.000";
			xlnx,clkout6-divide = <0xc>;
			xlnx,clkout6-drives = "BUFG";
			xlnx,clkout6-dyn-ps = <0x0>;
			xlnx,clkout6-grouping = "Auto";
			xlnx,clkout6-matched-routing = <0x0>;
			xlnx,clkout6-mbufgce-mode = "PERFORMANCE";
			xlnx,clkout6-requested-duty-cycle = "50.000";
			xlnx,clkout6-requested-out-freq = "100.000";
			xlnx,clkout6-requested-phase = "0.000";
			xlnx,clkout6-sequence-number = <0x1>;
			xlnx,clkout6-used = <0x0>;
			xlnx,clkout7-actual-duty-cycle = "50.00";
			xlnx,clkout7-actual-out-freq = "99.99900";
			xlnx,clkout7-actual-phase = "0.000";
			xlnx,clkout7-divide = <0xc>;
			xlnx,clkout7-drives = "BUFG";
			xlnx,clkout7-dyn-ps = <0x0>;
			xlnx,clkout7-grouping = "Auto";
			xlnx,clkout7-matched-routing = <0x0>;
			xlnx,clkout7-mbufgce-mode = "PERFORMANCE";
			xlnx,clkout7-requested-duty-cycle = "50.000";
			xlnx,clkout7-requested-out-freq = "100.000";
			xlnx,clkout7-requested-phase = "0.000";
			xlnx,clkout7-sequence-number = <0x1>;
			xlnx,clkout7-used = <0x0>;
			xlnx,clkoutfb-phase-ctrl = <0x0>;
			xlnx,compensation = "AUTO";
			xlnx,d-max = "107.000";
			xlnx,d-min = "1.000";
			xlnx,daddr-port = "daddr";
			xlnx,dclk-port = "dclk";
			xlnx,den-port = "den";
			xlnx,deskew-delay-en1 = "FALSE";
			xlnx,deskew-delay-en2 = "FALSE";
			xlnx,deskew-delay-path1 = "FALSE";
			xlnx,deskew-delay-path2 = "FALSE";
			xlnx,deskew-delay1 = <0x0>;
			xlnx,deskew-delay2 = <0x0>;
			xlnx,deskew-fb1 = <0x1>;
			xlnx,deskew-fb2 = <0x1>;
			xlnx,deskew-in1 = <0x0>;
			xlnx,deskew-in2 = <0x0>;
			xlnx,deskew-lock-circuit-en1 = <0x0>;
			xlnx,deskew-lock-circuit-en2 = <0x0>;
			xlnx,din-port = "din";
			xlnx,divclk-divide = <0x3>;
			xlnx,divide1-auto = "0.0";
			xlnx,divide2-auto = "0.0";
			xlnx,divide3-auto = "0.0";
			xlnx,divide4-auto = "0.0";
			xlnx,divide5-auto = "0.0";
			xlnx,divide6-auto = "0.0";
			xlnx,divide7-auto = "0.0";
			xlnx,dout-port = "dout";
			xlnx,drdy-port = "drdy";
			xlnx,drp-addr-set1 = "00000328 0000032c 00000330 00000334 00000338 0000033c 00000340 00000344 00000348 0000034c 00000350 00000354 00000358 0000035c 00000360 00000364 00000368 0000036c 00000370 00000374 00000378 0000037c 00000380 00000384 00000388 0000038c 00000390 00000394 00000398 0000039c 000003a0 000003a4 000003a8 000003ac 000003b0 000003b4 000003b8 000003bc 000003c0 000003c4 000003c8 000003cc 000003d0 000003d4 000003d8 000003dc 000003e0 000003e4 000003e8 000003ec 000003f0 000003f4 000003f8 000003fc";
			xlnx,drp-addr-set2 = "00000328 0000032c 00000330 00000334 00000338 0000033c 00000340 00000344 00000348 0000034c 00000350 00000354 00000358 0000035c 00000360 00000364 00000368 0000036c 00000370 00000374 00000378 0000037c 00000380 00000384 00000388 0000038c 00000390 00000394 00000398 0000039c 000003a0 000003a4 000003a8 000003ac 000003b0 000003b4 000003b8 000003bc 000003c0 000003c4 000003c8 000003cc 000003d0 000003d4 000003d8 000003dc 000003e0 000003e4 000003e8 000003ec 000003f0 000003f4 000003f8 000003fc";
			xlnx,drp-addr-set3 = "00000328 0000032c 00000330 00000334 00000338 0000033c 00000340 00000344 00000348 0000034c 00000350 00000354 00000358 0000035c 00000360 00000364 00000368 0000036c 00000370 00000374 00000378 0000037c 00000380 00000384 00000388 0000038c 00000390 00000394 00000398 0000039c 000003a0 000003a4 000003a8 000003ac 000003b0 000003b4 000003b8 000003bc 000003c0 000003c4 000003c8 000003cc 000003d0 000003d4 000003d8 000003dc 000003e0 000003e4 000003e8 000003ec 000003f0 000003f4 000003f8 000003fc";
			xlnx,drp-data-set1 = "4b06 0001 1600 8787 1b00 0202 0a00 0303 0a00 0303 0a00 0303 f37c 7c4d d042 ebd8 ec5f edfb aacd 4428 002f 0000 0400 0101 000f 0006 0000 0000 0e80 40e1 43e9 1188 0008 0001 0000 00c0 0dfd 0961 0001 0000 068b 0a00 0303 0a00 0303 0a00 0303 0000 0000 0000 0000 0000 0f00 0001";
			xlnx,drp-data-set2 = "4b06 0001 1600 8787 1a00 0202 0b00 0101 0a00 0000 0a00 0101 f37c 7c4d d042 ebd8 ec5f edfb aacd 4428 002f 0000 0400 0101 000f 0006 0000 0000 0e80 40e1 43e9 1188 0008 0001 0000 00c0 0dfd 0961 0001 0000 068b 0a00 0303 0b00 0101 0a00 0202 0000 0000 0000 0000 0000 0f00 0001";
			xlnx,drp-data-set3 = "4b06 0001 1600 8787 1b00 0202 0a00 0303 0a00 0303 0a00 0303 f37c 7c4d d042 ebd8 ec5f edfb aacd 4428 002f 0000 0400 0101 000f 0006 0000 0000 0e80 40e1 43e9 1188 0008 0001 0000 00c0 0dfd 0961 0001 0000 068b 0a00 0303 0a00 0303 0a00 0303 0000 0000 0000 0000 0000 0f00 0001";
			xlnx,dwe-port = "dwe";
			xlnx,enable-clock-monitor = <0x0>;
			xlnx,enable-pll0 = <0x0>;
			xlnx,enable-pll1 = <0x0>;
			xlnx,enable-user-clock0 = <0x0>;
			xlnx,enable-user-clock1 = <0x0>;
			xlnx,enable-user-clock2 = <0x0>;
			xlnx,enable-user-clock3 = <0x0>;
			xlnx,feedback-source = "FDBK_AUTO";
			xlnx,inclk-sum-row0 = "Input Clock   Freq (MHz)    Input Jitter (UI)";
			xlnx,inclk-sum-row1 = "primary       100.000        0.010";
			xlnx,inclk-sum-row2 = "secondary      100.000        0.010";
			xlnx,input-clk-stopped-port = "input_clk_stopped";
			xlnx,interface-selection = <0x1>;
			xlnx,jitter-sel = "No_Jitter";
			xlnx,locked-deskew1-port = "locked_deskew1";
			xlnx,locked-deskew2-port = "locked_deskew2";
			xlnx,locked-fb-port = "locked_fb";
			xlnx,locked-port = "locked";
			xlnx,m-max = "432.000";
			xlnx,m-min = "5.000";
			xlnx,mmcmbufgcediv = <0x0>;
			xlnx,mmcmbufgcediv1 = <0x0>;
			xlnx,mmcmbufgcediv2 = <0x0>;
			xlnx,mmcmbufgcediv3 = <0x0>;
			xlnx,mmcmbufgcediv4 = <0x0>;
			xlnx,mmcmbufgcediv5 = <0x0>;
			xlnx,mmcmbufgcediv6 = <0x0>;
			xlnx,mmcmbufgcediv7 = <0x0>;
			xlnx,num-out-clks = <0x1>;
			xlnx,numbufg = <0x0>;
			xlnx,numbufgce = <0x0>;
			xlnx,nummbufgce = <0x0>;
			xlnx,o-max = "432.000";
			xlnx,o-min = "3.000";
			xlnx,outclk-sum-row0a = "Output    Output      Phase     Duty      Pk-to-Pk        Phase";
			xlnx,outclk-sum-row0b = "Clock    Freq (MHz) (degrees) Cycle () Jitter (ps)  Error (ps)";
			xlnx,outclk-sum-row1 = "no clk_out1 output";
			xlnx,outclk-sum-row2 = "no clk_out2 output";
			xlnx,outclk-sum-row3 = "no clk_out3 output";
			xlnx,outclk-sum-row4 = "no clk_out4 output";
			xlnx,outclk-sum-row5 = "no clk_out5 output";
			xlnx,outclk-sum-row6 = "no clk_out6 output";
			xlnx,outclk-sum-row7 = "no clk_out7 output";
			xlnx,override-primitive = <0x0>;
			xlnx,phaseshift-mode = "LATENCY";
			xlnx,pllbufgcediv = <0x0>;
			xlnx,pllbufgcediv1 = <0x0>;
			xlnx,pllbufgcediv2 = <0x0>;
			xlnx,pllbufgcediv3 = <0x0>;
			xlnx,pllbufgcediv4 = <0x0>;
			xlnx,power-down-port = "power_down";
			xlnx,precision = <0x1>;
			xlnx,prim-in-freq = "33.333";
			xlnx,prim-source = "No_buffer";
			xlnx,primary-port = "clk_in1";
			xlnx,primitive = "MMCM";
			xlnx,psclk-port = "psclk";
			xlnx,psdone-port = "psdone";
			xlnx,psen-port = "psen";
			xlnx,psincdec-port = "psincdec";
			xlnx,ref-clk-freq = <0x64>;
			xlnx,ref-jitter1 = "0.010";
			xlnx,ref-jitter2 = "0.010";
			xlnx,reset-port = "reset";
			xlnx,reset-type = "ACTIVE_HIGH";
			xlnx,safeclock-startup-mode = "DESKEW_MODE";
			xlnx,secondary-in-freq = <0x30>;
			xlnx,secondary-port = "clk_in2";
			xlnx,secondary-source = "Single_ended_clock_capable_pin";
			xlnx,sim-device = "VERSAL_AI_CORE";
			xlnx,ss-mod-period = <0xfa0>;
			xlnx,ss-mod-time = "0.004";
			xlnx,ss-mode = "CENTER_HIGH";
			xlnx,use-clkfb-stopped = <0x0>;
			xlnx,use-clock-sequencing = <0x0>;
			xlnx,use-dyn-phase-shift = <0x0>;
			xlnx,use-dyn-reconfig = <0x1>;
			xlnx,use-freq-synth = <0x1>;
			xlnx,use-inclk-stopped = <0x0>;
			xlnx,use-inclk-switchover = <0x0>;
			xlnx,use-locked = <0x1>;
			xlnx,use-locked-deskew1 = <0x0>;
			xlnx,use-locked-deskew2 = <0x0>;
			xlnx,use-locked-fb = <0x0>;
			xlnx,use-min-power = <0x0>;
			xlnx,use-phase-alignment = <0x0>;
			xlnx,use-power-down = <0x1>;
			xlnx,use-reset = <0x1>;
			xlnx,use-safe-clock-startup = <0x0>;
			xlnx,use-spread-spectrum = "FALSE";
			xlnx,user-clk-freq0 = <0x64>;
			xlnx,user-clk-freq1 = <0x64>;
			xlnx,user-clk-freq2 = <0x64>;
			xlnx,user-clk-freq3 = <0x64>;
			xlnx,vco-max = "4320.000";
			xlnx,vco-min = "2160.000";
			xlnx,zhold = "FALSE";
		};

		misc_clk_1 {
			#clock-cells = <0x0>;
			clock-frequency = <0x1fca054>;
			compatible = "fixed-clock";
			phandle = <0xf>;
		};

		clk_wizard@80033000 {
			clock-names = "s_axi_aclk", "clk_in1";
			clocks = <0xe 0xf>;
			compatible = "xlnx,clk-wizard-1.0";
			reg = <0x0 0x80033000 0x0 0x1000>;
			xlnx,actual-pfd = "11.11100";
			xlnx,actual-vco = "2999.97000";
			xlnx,auto-nummbufgce = <0x0>;
			xlnx,auto-primitive = "MMCM";
			xlnx,bandwidth = "OPTIMIZED";
			xlnx,bufgce-div-ce-type = "SYNC";
			xlnx,cddcdone-port = "cddcdone";
			xlnx,cddcreq-port = "cddcreq";
			xlnx,ce-sync-ext = <0x0>;
			xlnx,ce-type = "SYNC";
			xlnx,clk-in-sel-port = "clk_in_sel";
			xlnx,clk-out1-port = "clk_out1";
			xlnx,clk-out2-port = "clk_out2";
			xlnx,clk-out3-port = "clk_out3";
			xlnx,clk-out4-port = "clk_out4";
			xlnx,clk-out5-port = "clk_out5";
			xlnx,clk-out6-port = "clk_out6";
			xlnx,clk-out7-port = "clk_out7";
			xlnx,clk-tree1 = <0x0>;
			xlnx,clk-tree2 = <0x0>;
			xlnx,clk-tree3 = <0x0>;
			xlnx,clk-tree4 = <0x0>;
			xlnx,clk-tree5 = <0x0>;
			xlnx,clk-tree6 = <0x0>;
			xlnx,clk-tree7 = <0x0>;
			xlnx,clkfb-bufg = <0x0>;
			xlnx,clkfb-deskew-port = "clkfb_deskew";
			xlnx,clkfb-in-port = "clkfb_in";
			xlnx,clkfb-in-signaling = "SINGLE";
			xlnx,clkfb-out-port = "clkfb_out";
			xlnx,clkfb-stopped-port = "clkfb_stopped";
			xlnx,clkfb1-deskew-port = "clkfb1_deskew";
			xlnx,clkfb2-deskew-port = "clkfb2_deskew";
			xlnx,clkfbin-ibuf = <0x0>;
			xlnx,clkfbin-ibufds = <0x0>;
			xlnx,clkfbin-obuf = <0x0>;
			xlnx,clkfbin-obufds = <0x0>;
			xlnx,clkfbout-bufg = <0x0>;
			xlnx,clkfbout-fract = <0x0>;
			xlnx,clkfbout-mult = <0x1>;
			xlnx,clkfbout-oddr = <0x0>;
			xlnx,clkfbout-phase = "0.000";
			xlnx,clkin-deskew-port = "clkin_deskew";
			xlnx,clkin1-bufg = <0x0>;
			xlnx,clkin1-deskew-port = "clkin1_deskew";
			xlnx,clkin1-ibuf = <0x0>;
			xlnx,clkin1-ibufds = <0x0>;
			xlnx,clkin1-jitter-ps = "100.0";
			xlnx,clkin1-period = "30.00030";
			xlnx,clkin2-bufg = <0x0>;
			xlnx,clkin2-deskew-port = "clkin2_deskew";
			xlnx,clkin2-ibuf = <0x0>;
			xlnx,clkin2-ibufds = <0x0>;
			xlnx,clkin2-jitter-ps = "100.0";
			xlnx,clkin2-period = "20.83333";
			xlnx,clkout1-actual-duty-cycle = "50.00";
			xlnx,clkout1-actual-out-freq = "499.99500";
			xlnx,clkout1-actual-phase = "0.000";
			xlnx,clkout1-divide = <0x6>;
			xlnx,clkout1-drives = "No_buffer";
			xlnx,clkout1-dyn-ps = <0x0>;
			xlnx,clkout1-grouping = "Auto";
			xlnx,clkout1-matched-routing = <0x0>;
			xlnx,clkout1-mbufgce-mode = "PERFORMANCE";
			xlnx,clkout1-requested-duty-cycle = "50.000";
			xlnx,clkout1-requested-out-freq = "100.000";
			xlnx,clkout1-requested-phase = "0.000";
			xlnx,clkout1-sequence-number = <0x1>;
			xlnx,clkout1-used = <0x1>;
			xlnx,clkout2-actual-duty-cycle = "50.00";
			xlnx,clkout2-actual-out-freq = "99.99900";
			xlnx,clkout2-actual-phase = "0.000";
			xlnx,clkout2-divide = <0xc>;
			xlnx,clkout2-drives = "BUFG";
			xlnx,clkout2-dyn-ps = <0x0>;
			xlnx,clkout2-grouping = "Auto";
			xlnx,clkout2-matched-routing = <0x0>;
			xlnx,clkout2-mbufgce-mode = "PERFORMANCE";
			xlnx,clkout2-requested-duty-cycle = "50.000";
			xlnx,clkout2-requested-out-freq = "100.000";
			xlnx,clkout2-requested-phase = "0.000";
			xlnx,clkout2-sequence-number = <0x1>;
			xlnx,clkout2-used = <0x0>;
			xlnx,clkout3-actual-duty-cycle = "50.00";
			xlnx,clkout3-actual-out-freq = "99.99900";
			xlnx,clkout3-actual-phase = "0.000";
			xlnx,clkout3-divide = <0xc>;
			xlnx,clkout3-drives = "BUFG";
			xlnx,clkout3-dyn-ps = <0x0>;
			xlnx,clkout3-grouping = "Auto";
			xlnx,clkout3-matched-routing = <0x0>;
			xlnx,clkout3-mbufgce-mode = "PERFORMANCE";
			xlnx,clkout3-requested-duty-cycle = "50.000";
			xlnx,clkout3-requested-out-freq = "100.000";
			xlnx,clkout3-requested-phase = "0.000";
			xlnx,clkout3-sequence-number = <0x1>;
			xlnx,clkout3-used = <0x0>;
			xlnx,clkout4-actual-duty-cycle = "50.00";
			xlnx,clkout4-actual-out-freq = "99.99900";
			xlnx,clkout4-actual-phase = "0.000";
			xlnx,clkout4-divide = <0xc>;
			xlnx,clkout4-drives = "BUFG";
			xlnx,clkout4-dyn-ps = <0x0>;
			xlnx,clkout4-grouping = "Auto";
			xlnx,clkout4-matched-routing = <0x0>;
			xlnx,clkout4-mbufgce-mode = "PERFORMANCE";
			xlnx,clkout4-requested-duty-cycle = "50.000";
			xlnx,clkout4-requested-out-freq = "100.000";
			xlnx,clkout4-requested-phase = "0.000";
			xlnx,clkout4-sequence-number = <0x1>;
			xlnx,clkout4-used = <0x0>;
			xlnx,clkout5-actual-duty-cycle = "50.00";
			xlnx,clkout5-actual-out-freq = "99.99900";
			xlnx,clkout5-actual-phase = "0.000";
			xlnx,clkout5-divide = <0xc>;
			xlnx,clkout5-drives = "BUFG";
			xlnx,clkout5-dyn-ps = <0x0>;
			xlnx,clkout5-grouping = "Auto";
			xlnx,clkout5-matched-routing = <0x0>;
			xlnx,clkout5-mbufgce-mode = "PERFORMANCE";
			xlnx,clkout5-requested-duty-cycle = "50.000";
			xlnx,clkout5-requested-out-freq = "100.000";
			xlnx,clkout5-requested-phase = "0.000";
			xlnx,clkout5-sequence-number = <0x1>;
			xlnx,clkout5-used = <0x0>;
			xlnx,clkout6-actual-duty-cycle = "50.00";
			xlnx,clkout6-actual-out-freq = "99.99900";
			xlnx,clkout6-actual-phase = "0.000";
			xlnx,clkout6-divide = <0xc>;
			xlnx,clkout6-drives = "BUFG";
			xlnx,clkout6-dyn-ps = <0x0>;
			xlnx,clkout6-grouping = "Auto";
			xlnx,clkout6-matched-routing = <0x0>;
			xlnx,clkout6-mbufgce-mode = "PERFORMANCE";
			xlnx,clkout6-requested-duty-cycle = "50.000";
			xlnx,clkout6-requested-out-freq = "100.000";
			xlnx,clkout6-requested-phase = "0.000";
			xlnx,clkout6-sequence-number = <0x1>;
			xlnx,clkout6-used = <0x0>;
			xlnx,clkout7-actual-duty-cycle = "50.00";
			xlnx,clkout7-actual-out-freq = "99.99900";
			xlnx,clkout7-actual-phase = "0.000";
			xlnx,clkout7-divide = <0xc>;
			xlnx,clkout7-drives = "BUFG";
			xlnx,clkout7-dyn-ps = <0x0>;
			xlnx,clkout7-grouping = "Auto";
			xlnx,clkout7-matched-routing = <0x0>;
			xlnx,clkout7-mbufgce-mode = "PERFORMANCE";
			xlnx,clkout7-requested-duty-cycle = "50.000";
			xlnx,clkout7-requested-out-freq = "100.000";
			xlnx,clkout7-requested-phase = "0.000";
			xlnx,clkout7-sequence-number = <0x1>;
			xlnx,clkout7-used = <0x0>;
			xlnx,clkoutfb-phase-ctrl = <0x0>;
			xlnx,compensation = "AUTO";
			xlnx,d-max = "107.000";
			xlnx,d-min = "1.000";
			xlnx,daddr-port = "daddr";
			xlnx,dclk-port = "dclk";
			xlnx,den-port = "den";
			xlnx,deskew-delay-en1 = "FALSE";
			xlnx,deskew-delay-en2 = "FALSE";
			xlnx,deskew-delay-path1 = "FALSE";
			xlnx,deskew-delay-path2 = "FALSE";
			xlnx,deskew-delay1 = <0x0>;
			xlnx,deskew-delay2 = <0x0>;
			xlnx,deskew-fb1 = <0x1>;
			xlnx,deskew-fb2 = <0x1>;
			xlnx,deskew-in1 = <0x0>;
			xlnx,deskew-in2 = <0x0>;
			xlnx,deskew-lock-circuit-en1 = <0x0>;
			xlnx,deskew-lock-circuit-en2 = <0x0>;
			xlnx,din-port = "din";
			xlnx,divclk-divide = <0x3>;
			xlnx,divide1-auto = "0.0";
			xlnx,divide2-auto = "0.0";
			xlnx,divide3-auto = "0.0";
			xlnx,divide4-auto = "0.0";
			xlnx,divide5-auto = "0.0";
			xlnx,divide6-auto = "0.0";
			xlnx,divide7-auto = "0.0";
			xlnx,dout-port = "dout";
			xlnx,drdy-port = "drdy";
			xlnx,drp-addr-set1 = "00000328 0000032c 00000330 00000334 00000338 0000033c 00000340 00000344 00000348 0000034c 00000350 00000354 00000358 0000035c 00000360 00000364 00000368 0000036c 00000370 00000374 00000378 0000037c 00000380 00000384 00000388 0000038c 00000390 00000394 00000398 0000039c 000003a0 000003a4 000003a8 000003ac 000003b0 000003b4 000003b8 000003bc 000003c0 000003c4 000003c8 000003cc 000003d0 000003d4 000003d8 000003dc 000003e0 000003e4 000003e8 000003ec 000003f0 000003f4 000003f8 000003fc";
			xlnx,drp-addr-set2 = "00000328 0000032c 00000330 00000334 00000338 0000033c 00000340 00000344 00000348 0000034c 00000350 00000354 00000358 0000035c 00000360 00000364 00000368 0000036c 00000370 00000374 00000378 0000037c 00000380 00000384 00000388 0000038c 00000390 00000394 00000398 0000039c 000003a0 000003a4 000003a8 000003ac 000003b0 000003b4 000003b8 000003bc 000003c0 000003c4 000003c8 000003cc 000003d0 000003d4 000003d8 000003dc 000003e0 000003e4 000003e8 000003ec 000003f0 000003f4 000003f8 000003fc";
			xlnx,drp-addr-set3 = "00000328 0000032c 00000330 00000334 00000338 0000033c 00000340 00000344 00000348 0000034c 00000350 00000354 00000358 0000035c 00000360 00000364 00000368 0000036c 00000370 00000374 00000378 0000037c 00000380 00000384 00000388 0000038c 00000390 00000394 00000398 0000039c 000003a0 000003a4 000003a8 000003ac 000003b0 000003b4 000003b8 000003bc 000003c0 000003c4 000003c8 000003cc 000003d0 000003d4 000003d8 000003dc 000003e0 000003e4 000003e8 000003ec 000003f0 000003f4 000003f8 000003fc";
			xlnx,drp-data-set1 = "4b06 0001 1600 8787 1b00 0101 0a00 0303 0a00 0303 0a00 0303 f37c 7c4d d042 ebd8 ec5f edfb aacd 4428 002f 0000 0400 0101 000f 0006 0000 0000 0e80 40e1 43e9 1188 0008 0001 0000 00c0 0dfd 0961 0001 0000 068b 0a00 0303 0a00 0303 0a00 0303 0000 0000 0000 0000 0000 0f00 0001";
			xlnx,drp-data-set2 = "4b06 0001 1600 8787 1a00 0202 0b00 0101 0a00 0000 0a00 0101 f37c 7c4d d042 ebd8 ec5f edfb aacd 4428 002f 0000 0400 0101 000f 0006 0000 0000 0e80 40e1 43e9 1188 0008 0001 0000 00c0 0dfd 0961 0001 0000 068b 0a00 0303 0b00 0101 0a00 0202 0000 0000 0000 0000 0000 0f00 0001";
			xlnx,drp-data-set3 = "4b06 0001 1600 8787 1b00 0101 0a00 0303 0a00 0303 0a00 0303 f37c 7c4d d042 ebd8 ec5f edfb aacd 4428 002f 0000 0400 0101 000f 0006 0000 0000 0e80 40e1 43e9 1188 0008 0001 0000 00c0 0dfd 0961 0001 0000 068b 0a00 0303 0a00 0303 0a00 0303 0000 0000 0000 0000 0000 0f00 0001";
			xlnx,dwe-port = "dwe";
			xlnx,enable-clock-monitor = <0x0>;
			xlnx,enable-pll0 = <0x0>;
			xlnx,enable-pll1 = <0x0>;
			xlnx,enable-user-clock0 = <0x0>;
			xlnx,enable-user-clock1 = <0x0>;
			xlnx,enable-user-clock2 = <0x0>;
			xlnx,enable-user-clock3 = <0x0>;
			xlnx,feedback-source = "FDBK_AUTO";
			xlnx,inclk-sum-row0 = "Input Clock   Freq (MHz)    Input Jitter (UI)";
			xlnx,inclk-sum-row1 = "primary       100.000        0.010";
			xlnx,inclk-sum-row2 = "secondary      100.000        0.010";
			xlnx,input-clk-stopped-port = "input_clk_stopped";
			xlnx,interface-selection = <0x1>;
			xlnx,jitter-sel = "No_Jitter";
			xlnx,locked-deskew1-port = "locked_deskew1";
			xlnx,locked-deskew2-port = "locked_deskew2";
			xlnx,locked-fb-port = "locked_fb";
			xlnx,locked-port = "locked";
			xlnx,m-max = "432.000";
			xlnx,m-min = "5.000";
			xlnx,mmcmbufgcediv = <0x0>;
			xlnx,mmcmbufgcediv1 = <0x0>;
			xlnx,mmcmbufgcediv2 = <0x0>;
			xlnx,mmcmbufgcediv3 = <0x0>;
			xlnx,mmcmbufgcediv4 = <0x0>;
			xlnx,mmcmbufgcediv5 = <0x0>;
			xlnx,mmcmbufgcediv6 = <0x0>;
			xlnx,mmcmbufgcediv7 = <0x0>;
			xlnx,num-out-clks = <0x1>;
			xlnx,numbufg = <0x0>;
			xlnx,numbufgce = <0x0>;
			xlnx,nummbufgce = <0x0>;
			xlnx,o-max = "432.000";
			xlnx,o-min = "3.000";
			xlnx,outclk-sum-row0a = "Output    Output      Phase     Duty      Pk-to-Pk        Phase";
			xlnx,outclk-sum-row0b = "Clock    Freq (MHz) (degrees) Cycle () Jitter (ps)  Error (ps)";
			xlnx,outclk-sum-row1 = "no clk_out1 output";
			xlnx,outclk-sum-row2 = "no clk_out2 output";
			xlnx,outclk-sum-row3 = "no clk_out3 output";
			xlnx,outclk-sum-row4 = "no clk_out4 output";
			xlnx,outclk-sum-row5 = "no clk_out5 output";
			xlnx,outclk-sum-row6 = "no clk_out6 output";
			xlnx,outclk-sum-row7 = "no clk_out7 output";
			xlnx,override-primitive = <0x0>;
			xlnx,phaseshift-mode = "LATENCY";
			xlnx,pllbufgcediv = <0x0>;
			xlnx,pllbufgcediv1 = <0x0>;
			xlnx,pllbufgcediv2 = <0x0>;
			xlnx,pllbufgcediv3 = <0x0>;
			xlnx,pllbufgcediv4 = <0x0>;
			xlnx,power-down-port = "power_down";
			xlnx,precision = <0x1>;
			xlnx,prim-in-freq = "33.333";
			xlnx,prim-source = "No_buffer";
			xlnx,primary-port = "clk_in1";
			xlnx,primitive = "MMCM";
			xlnx,psclk-port = "psclk";
			xlnx,psdone-port = "psdone";
			xlnx,psen-port = "psen";
			xlnx,psincdec-port = "psincdec";
			xlnx,ref-clk-freq = <0x64>;
			xlnx,ref-jitter1 = "0.010";
			xlnx,ref-jitter2 = "0.010";
			xlnx,reset-port = "reset";
			xlnx,reset-type = "ACTIVE_HIGH";
			xlnx,safeclock-startup-mode = "DESKEW_MODE";
			xlnx,secondary-in-freq = <0x30>;
			xlnx,secondary-port = "clk_in2";
			xlnx,secondary-source = "Single_ended_clock_capable_pin";
			xlnx,sim-device = "VERSAL_AI_CORE";
			xlnx,ss-mod-period = <0xfa0>;
			xlnx,ss-mod-time = "0.004";
			xlnx,ss-mode = "CENTER_HIGH";
			xlnx,use-clkfb-stopped = <0x0>;
			xlnx,use-clock-sequencing = <0x0>;
			xlnx,use-dyn-phase-shift = <0x0>;
			xlnx,use-dyn-reconfig = <0x1>;
			xlnx,use-freq-synth = <0x1>;
			xlnx,use-inclk-stopped = <0x0>;
			xlnx,use-inclk-switchover = <0x0>;
			xlnx,use-locked = <0x1>;
			xlnx,use-locked-deskew1 = <0x0>;
			xlnx,use-locked-deskew2 = <0x0>;
			xlnx,use-locked-fb = <0x0>;
			xlnx,use-min-power = <0x0>;
			xlnx,use-phase-alignment = <0x0>;
			xlnx,use-power-down = <0x1>;
			xlnx,use-reset = <0x1>;
			xlnx,use-safe-clock-startup = <0x0>;
			xlnx,use-spread-spectrum = "FALSE";
			xlnx,user-clk-freq0 = <0x64>;
			xlnx,user-clk-freq1 = <0x64>;
			xlnx,user-clk-freq2 = <0x64>;
			xlnx,user-clk-freq3 = <0x64>;
			xlnx,vco-max = "4320.000";
			xlnx,vco-min = "2160.000";
			xlnx,zhold = "FALSE";
		};

		shell_utils_frequency_counter@80036000 {
			clock-names = "s_axi_aclk";
			clocks = <0xf>;
			compatible = "xlnx,shell-utils-frequency-counter-1.0";
			reg = <0x0 0x80036000 0x0 0x1000>;
		};

		shell_utils_frequency_counter@80034000 {
			clock-names = "s_axi_aclk";
			clocks = <0xf>;
			compatible = "xlnx,shell-utils-frequency-counter-1.0";
			reg = <0x0 0x80034000 0x0 0x1000>;
		};

		shell_utils_frequency_counter@80035000 {
			clock-names = "s_axi_aclk";
			clocks = <0xf>;
			compatible = "xlnx,shell-utils-frequency-counter-1.0";
			reg = <0x0 0x80035000 0x0 0x1000>;
		};

		gpio@80030000 {
			status = "disabled";
			#gpio-cells = <0x3>;
			clock-names = "s_axi_aclk";
			clocks = <0xe>;
			compatible = "xlnx,axi-gpio-2.0", "xlnx,xps-gpio-1.00.a";
			gpio-controller;
			reg = <0x0 0x80030000 0x0 0x1000>;
			xlnx,all-inputs = <0x0>;
			xlnx,all-inputs-2 = <0x1>;
			xlnx,all-outputs = <0x1>;
			xlnx,all-outputs-2 = <0x0>;
			xlnx,dout-default = <0x10000ff>;
			xlnx,dout-default-2 = <0x0>;
			xlnx,gpio-width = <0x20>;
			xlnx,gpio2-width = <0x20>;
			xlnx,interrupt-present = <0x0>;
			xlnx,is-dual = <0x1>;
			xlnx,tri-default = <0xffffffff>;
			xlnx,tri-default-2 = <0xffffffff>;
		};

		gpio@80031000 {
			status = "disabled";
			#gpio-cells = <0x3>;
			clock-names = "s_axi_aclk";
			clocks = <0xe>;
			compatible = "xlnx,axi-gpio-2.0", "xlnx,xps-gpio-1.00.a";
			gpio-controller;
			reg = <0x0 0x80031000 0x0 0x1000>;
			xlnx,all-inputs = <0x1>;
			xlnx,all-inputs-2 = <0x0>;
			xlnx,all-outputs = <0x0>;
			xlnx,all-outputs-2 = <0x1>;
			xlnx,dout-default = <0x0>;
			xlnx,dout-default-2 = <0x0>;
			xlnx,gpio-width = <0x20>;
			xlnx,gpio2-width = <0x20>;
			xlnx,interrupt-present = <0x0>;
			xlnx,is-dual = <0x1>;
			xlnx,tri-default = <0xffffffff>;
			xlnx,tri-default-2 = <0xffffffff>;
		};

		shell_utils_uuid_rom@20102002000 {
			clock-names = "S_AXI_ACLK";
			clocks = <0xe>;
			compatible = "xlnx,shell-utils-uuid-rom-2.0";
			reg = <0x201 0x2002000 0x0 0x1000>;
			xlnx,initial-uuid = <0x0>;
			xlnx,memory-init = <0x0>;
			xlnx,xdevicefamily = "versal";
		};

		xrt_queue@402000000 {
			clock-names = "s00_axi_aclk";
			clocks = <0xe>;
			compatible = "xlnx,xrt-queue-1.1";
			reg = <0x4 0x2000000 0x0 0x1000>;
			xlnx,include-bram = <0x0>;
			xlnx,s00-axi-addr-width = <0x9>;
			xlnx,s00-axi-data-width = <0x20>;
			xlnx,s02-axi-mem-addr-width = <0xb>;
			xlnx,s02-axi-mem-data-width = <0x20>;
			xlnx,s02-axi-mem-id-width = <0x1>;
			interrupt-parent = <0x5>;
			interrupts = <0x0 0x5c 0x1>;
			phandle = <0x3f>;
		};

		xrt_queue@402010000 {
			clock-names = "s00_axi_aclk";
			clocks = <0xe>;
			compatible = "xlnx,xrt-queue-1.1";
			reg = <0x4 0x2010000 0x0 0x1000>;
			xlnx,include-bram = <0x0>;
			xlnx,s00-axi-addr-width = <0x9>;
			xlnx,s00-axi-data-width = <0x20>;
			xlnx,s02-axi-mem-addr-width = <0xb>;
			xlnx,s02-axi-mem-data-width = <0x20>;
			xlnx,s02-axi-mem-id-width = <0x1>;
			interrupt-parent = <0x5>;
			interrupts = <0x0 0x5f 0x1>;
			phandle = <0x3d>;
		};

		xrt_queue@402011000 {
			clock-names = "s00_axi_aclk";
			clocks = <0xe>;
			compatible = "xlnx,xrt-queue-1.1";
			reg = <0x4 0x2011000 0x0 0x1000>;
			xlnx,include-bram = <0x0>;
			xlnx,s00-axi-addr-width = <0x9>;
			xlnx,s00-axi-data-width = <0x20>;
			xlnx,s02-axi-mem-addr-width = <0xb>;
			xlnx,s02-axi-mem-data-width = <0x20>;
			xlnx,s02-axi-mem-id-width = <0x1>;
			interrupt-parent = <0x5>;
			interrupts = <0x0 0x60 0x1>;
			phandle = <0x3c>;
		};

		xrt_queue@402012000 {
			clock-names = "s00_axi_aclk";
			clocks = <0xe>;
			compatible = "xlnx,xrt-queue-1.1";
			reg = <0x4 0x2012000 0x0 0x1000>;
			xlnx,include-bram = <0x0>;
			xlnx,s00-axi-addr-width = <0x9>;
			xlnx,s00-axi-data-width = <0x20>;
			xlnx,s02-axi-mem-addr-width = <0xb>;
			xlnx,s02-axi-mem-data-width = <0x20>;
			xlnx,s02-axi-mem-id-width = <0x1>;
			interrupt-parent = <0x5>;
			interrupts = <0x0 0x61 0x1>;
			phandle = <0x3b>;
		};

		xrt_queue@402013000 {
			clock-names = "s00_axi_aclk";
			clocks = <0xe>;
			compatible = "xlnx,xrt-queue-1.1";
			reg = <0x4 0x2013000 0x0 0x1000>;
			xlnx,include-bram = <0x0>;
			xlnx,s00-axi-addr-width = <0x9>;
			xlnx,s00-axi-data-width = <0x20>;
			xlnx,s02-axi-mem-addr-width = <0xb>;
			xlnx,s02-axi-mem-data-width = <0x20>;
			xlnx,s02-axi-mem-id-width = <0x1>;
			interrupt-parent = <0x5>;
			interrupts = <0x0 0x62 0x1>;
			phandle = <0x3a>;
		};

		shell_utils_versal_remap@20108000000 {
			clock-names = "AXI_ACLK";
			clocks = <0xe>;
			compatible = "xlnx,shell-utils-versal-remap-1.0";
			reg = <0x201 0x8000000 0x0 0x8000000>;
			xlnx,master-addr = <0x3800>;
			xlnx,transparent-bits = <0x1b>;
			xlnx,xdevicefamily = "versal";
		};

		shell_utils_versal_remap@20206000000 {
			clock-names = "AXI_ACLK";
			clocks = <0xe>;
			compatible = "xlnx,shell-utils-versal-remap-1.0";
			reg = <0x202 0x6000000 0x0 0x1000000>;
			xlnx,master-addr = <0x3600>;
			xlnx,transparent-bits = <0x18>;
			xlnx,xdevicefamily = "versal";
		};

		ai_engine@20000000000 {
			#address-cells = <0x2>;
			#size-cells = <0x2>;
			compatible = "xlnx,ai-engine-2.0", "xlnx,ai-engine-v1.0";
			interrupt-names = "interrupt1", "interrupt2", "interrupt3";
			interrupt-parent = <0x5>;
			interrupts = <0x0 0x94 0x4 0x0 0x95 0x4 0x0 0x96 0x4>;
			power-domains = <0x7 0x18224072>;
			reg = <0x200 0x0 0x1 0x0>;

			aie_partition@0 {
				reg = <0x0 0x0 0x32 0x9>;
				xlnx,partition-id = <0x1>;
			};
		};

		axi_dbg_hub@20205800000 {
			clock-names = "aclk";
			clocks = <0x10>;
			compatible = "xlnx,axi-dbg-hub-2.0";
			reg = <0x202 0x5800000 0x0 0x200000>;
			xlnx,addr-offset = <0x202 0x5800000>;
			xlnx,addr-range = <0x200000>;
			xlnx,axi-addr-width = <0x40>;
			xlnx,axi-data-width = <0x80>;
			xlnx,axi-id-width = <0x2>;
			xlnx,axis-tdata-width = <0x20>;
			xlnx,num-debug-cores = <0x0>;
			xlnx,num-rd-outstanding-txn = <0x1>;
			xlnx,num-wr-outstanding-txn = <0x1>;
		};

		misc_clk_2 {
			#clock-cells = <0x0>;
			clock-frequency = <0xee6b271>;
			compatible = "fixed-clock";
			phandle = <0x10>;
		};

		gpio@20200000000 {
			status = "disabled";
			#gpio-cells = <0x3>;
			clock-names = "s_axi_aclk";
			clocks = <0xe>;
			compatible = "xlnx,axi-gpio-2.0", "xlnx,xps-gpio-1.00.a";
			gpio-controller;
			reg = <0x202 0x0 0x0 0x1000>;
			xlnx,all-inputs = <0x0>;
			xlnx,all-inputs-2 = <0x0>;
			xlnx,all-outputs = <0x0>;
			xlnx,all-outputs-2 = <0x0>;
			xlnx,dout-default = <0x0>;
			xlnx,dout-default-2 = <0x0>;
			xlnx,gpio-width = <0x1>;
			xlnx,gpio2-width = <0x20>;
			xlnx,interrupt-present = <0x0>;
			xlnx,is-dual = <0x0>;
			xlnx,tri-default = <0xffffffff>;
			xlnx,tri-default-2 = <0xffffffff>;
		};

		axi_bram_ctrl@20204000000 {
			clock-names = "s_axi_aclk";
			clocks = <0x11>;
			compatible = "xlnx,axi-bram-ctrl-4.1";
			reg = <0x202 0x4000000 0x0 0x20000>;
			xlnx,bram-addr-width = <0xb>;
			xlnx,bram-inst-mode = "EXTERNAL";
			xlnx,ecc = <0x0>;
			xlnx,ecc-onoff-reset-value = <0x0>;
			xlnx,ecc-type = <0x0>;
			xlnx,fault-inject = <0x0>;
			xlnx,memory-depth = <0x800>;
			xlnx,rd-cmd-optimization = <0x0>;
			xlnx,read-latency = <0x1>;
			xlnx,s-axi-ctrl-addr-width = <0x20>;
			xlnx,s-axi-ctrl-data-width = <0x20>;
			xlnx,s-axi-id-width = <0x1>;
			xlnx,s-axi-supports-narrow-burst = <0x0>;
			xlnx,single-port-bram = <0x1>;
		};

		misc_clk_3 {
			#clock-cells = <0x0>;
			clock-frequency = <0x11e19747>;
			compatible = "fixed-clock";
			phandle = <0x11>;
		};
	};

	chosen {
		bootargs = "console=ttyUL0  earlycon=uartlite_a,0x402020000,115200n8 clk_ignore_unused root=/dev/mmcblk0p2 rw rootwait";
		stdout-path = "serial0:115200n8";
	};

	aliases {
		serial0 = "/amba_pl@0/serial@402020000";
		i2c0 = "/amba/i2c@ff020000";
		i2c1 = "/amba/i2c@ff030000";
		spi0 = "/amba/spi@f1010000";
	};

	memory@C080000000 {
		device_type = "memory";
		reg = <0x0 0x0 0x0 0x35ff0000 0xc0 0x80000000 0x3 0x80000000>;
	};

	reserved-memory {
		#address-cells = <0x2>;
		#size-cells = <0x2>;
		ranges;

		buffer@0 {
			no-map;
			reg = <0xc1 0x00000000 0x3 0x00000000>;
			phandle = <0x12>;
		};

		buffer0@36000000 {
			no-map;
			reg = <0x0 0x36000000 0x0 0x1000000>;
			phandle = <0x13>;
		};

		buffer@37000000 {
			no-map;
			reg = <0x0 0x37000000 0x0 0x1000000>;
			phandle = <0x14>;
		};
	};

	zyxclmm_drm {
		compatible = "xlnx,zocl-versal";
		status = "okay";
		memory-region = <0x12>;
		reg = <0x202 0x0 0x0 0x100000>;
	};

	ert_hw {
		compatible = "xlnx,embedded_sched_versal";
		status = "okay";
		xlnx,xgq_buffer = <0x13>;
		xlnx,xgq_device = <0x3d 0x3c 0x3b 0x3a>;
		interrupt-names = "irq_sq";
	};

	rpu-channel {
		compatible = "xlnx,rpu-channel";
		xlnx,xgq_buffer = <0x14>;
		xlnx,xgq_device = <0x3f>;
		interrupt-names = "irq_sq";
	};
};
